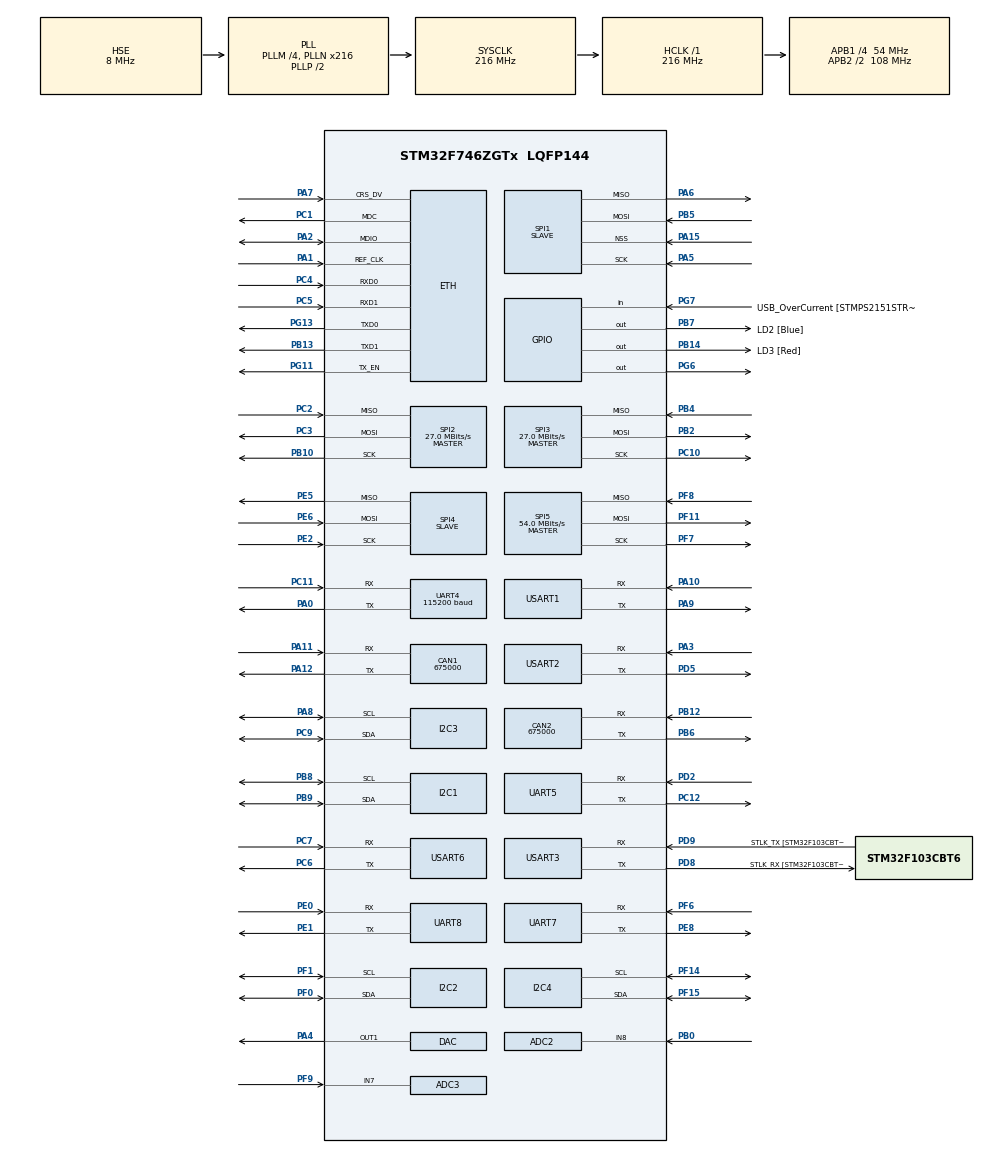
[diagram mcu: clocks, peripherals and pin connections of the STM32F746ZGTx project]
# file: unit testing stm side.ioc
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ADC1.Channel-1\#ChannelRegularConversion=ADC_CHANNEL_8
ADC1.ClockPrescaler=ADC_CLOCK_SYNC_PCLK_DIV4
ADC1.NbrOfConversionFlag=1
ADC1.Rank-1\#ChannelRegularConversion=1
ADC1.SamplingTime-1\#ChannelRegularConversion=ADC_SAMPLETIME_3CYCLES
ADC1.master=1
ADC2.Channel-2\#ChannelRegularConversion=ADC_CHANNEL_8
ADC2.ClockPrescaler=ADC_CLOCK_SYNC_PCLK_DIV4
ADC2.NbrOfConversionFlag=1
ADC2.Rank-2\#ChannelRegularConversion=1
ADC2.SamplingTime-2\#ChannelRegularConversion=ADC_SAMPLETIME_3CYCLES
ADC3.Channel-0\#ChannelRegularConversion=ADC_CHANNEL_7
ADC3.ClockPrescaler=ADC_CLOCK_SYNC_PCLK_DIV4
ADC3.NbrOfConversionFlag=1
ADC3.Rank-0\#ChannelRegularConversion=1
ADC3.SamplingTime-0\#ChannelRegularConversion=ADC_SAMPLETIME_3CYCLES
CAN1.BS1=CAN_BS1_2TQ
CAN1.BS2=CAN_BS2_2TQ
CAN1.CalculateBaudRate=675000
CAN1.CalculateTimeBit=1481
CAN1.CalculateTimeQuantum=296.2962962962963
CAN2.BS1=CAN_BS1_2TQ
CAN2.BS2=CAN_BS2_2TQ
CAN2.CalculateBaudRate=675000
CAN2.CalculateTimeBit=1481
CAN2.CalculateTimeQuantum=296.2962962962963
Dma.I2C1_RX.0.Direction=DMA_PERIPH_TO_MEMORY
Dma.I2C1_RX.0.FIFOMode=DMA_FIFOMODE_DISABLE
Dma.I2C1_RX.0.Instance=DMA1_Stream5
Dma.I2C1_RX.0.MemDataAlignment=DMA_MDATAALIGN_BYTE
Dma.I2C1_RX.0.MemInc=DMA_MINC_ENABLE
Dma.I2C1_RX.0.Mode=DMA_NORMAL
Dma.I2C1_RX.0.PeriphDataAlignment=DMA_PDATAALIGN_BYTE
Dma.I2C1_RX.0.PeriphInc=DMA_PINC_DISABLE
Dma.I2C1_RX.0.Priority=DMA_PRIORITY_LOW
Dma.I2C3_RX.8.Direction=DMA_PERIPH_TO_MEMORY
Dma.I2C3_RX.8.FIFOMode=DMA_FIFOMODE_DISABLE
Dma.I2C3_RX.8.Instance=DMA1_Stream1
Dma.I2C3_RX.8.MemDataAlignment=DMA_MDATAALIGN_BYTE
Dma.I2C3_RX.8.MemInc=DMA_MINC_ENABLE
Dma.I2C3_RX.8.Mode=DMA_NORMAL
Dma.I2C3_RX.8.PeriphDataAlignment=DMA_PDATAALIGN_BYTE
Dma.I2C3_RX.8.PeriphInc=DMA_PINC_DISABLE
Dma.I2C3_RX.8.Priority=DMA_PRIORITY_LOW
Dma.Request0=I2C1_RX
Dma.Request1=SPI1_RX
Dma.Request10=SPI4_TX
Dma.Request11=UART8_RX
Dma.Request12=USART1_RX
Dma.Request13=USART1_TX
Dma.Request14=USART6_RX
Dma.Request15=USART6_TX
Dma.Request2=SPI2_RX
Dma.Request3=UART4_TX
Dma.Request4=UART5_TX
Dma.Request5=SPI1_TX
Dma.Request6=UART4_RX
Dma.Request7=UART5_RX
Dma.Request8=I2C3_RX
Dma.Request9=SPI4_RX
Dma.SPI1_RX.1.Direction=DMA_PERIPH_TO_MEMORY
Dma.SPI1_RX.1.FIFOMode=DMA_FIFOMODE_DISABLE
Dma.SPI1_RX.1.Instance=DMA2_Stream2
Dma.SPI1_RX.1.MemDataAlignment=DMA_MDATAALIGN_BYTE
Dma.SPI1_RX.1.MemInc=DMA_MINC_ENABLE
Dma.SPI1_RX.1.Mode=DMA_NORMAL
Dma.SPI1_RX.1.PeriphDataAlignment=DMA_PDATAALIGN_BYTE
Dma.SPI1_RX.1.PeriphInc=DMA_PINC_DISABLE
Dma.SPI1_RX.1.Priority=DMA_PRIORITY_LOW
Dma.SPI1_TX.5.Direction=DMA_MEMORY_TO_PERIPH
Dma.SPI1_TX.5.FIFOMode=DMA_FIFOMODE_DISABLE
Dma.SPI1_TX.5.Instance=DMA2_Stream3
Dma.SPI1_TX.5.MemDataAlignment=DMA_MDATAALIGN_BYTE
Dma.SPI1_TX.5.MemInc=DMA_MINC_ENABLE
Dma.SPI1_TX.5.Mode=DMA_NORMAL
Dma.SPI1_TX.5.PeriphDataAlignment=DMA_PDATAALIGN_BYTE
Dma.SPI1_TX.5.PeriphInc=DMA_PINC_DISABLE
Dma.SPI1_TX.5.Priority=DMA_PRIORITY_LOW
Dma.SPI2_RX.2.Direction=DMA_PERIPH_TO_MEMORY
Dma.SPI2_RX.2.FIFOMode=DMA_FIFOMODE_DISABLE
Dma.SPI2_RX.2.Instance=DMA1_Stream3
Dma.SPI2_RX.2.MemDataAlignment=DMA_MDATAALIGN_BYTE
Dma.SPI2_RX.2.MemInc=DMA_MINC_ENABLE
Dma.SPI2_RX.2.Mode=DMA_NORMAL
Dma.SPI2_RX.2.PeriphDataAlignment=DMA_PDATAALIGN_BYTE
Dma.SPI2_RX.2.PeriphInc=DMA_PINC_DISABLE
Dma.SPI2_RX.2.Priority=DMA_PRIORITY_LOW
Dma.SPI4_RX.9.Direction=DMA_PERIPH_TO_MEMORY
Dma.SPI4_RX.9.FIFOMode=DMA_FIFOMODE_DISABLE
Dma.SPI4_RX.9.Instance=DMA2_Stream0
Dma.SPI4_RX.9.MemDataAlignment=DMA_MDATAALIGN_BYTE
Dma.SPI4_RX.9.MemInc=DMA_MINC_ENABLE
Dma.SPI4_RX.9.Mode=DMA_NORMAL
Dma.SPI4_RX.9.PeriphDataAlignment=DMA_PDATAALIGN_BYTE
Dma.SPI4_RX.9.PeriphInc=DMA_PINC_DISABLE
Dma.SPI4_RX.9.Priority=DMA_PRIORITY_LOW
Dma.SPI4_TX.10.Direction=DMA_MEMORY_TO_PERIPH
Dma.SPI4_TX.10.FIFOMode=DMA_FIFOMODE_DISABLE
Dma.SPI4_TX.10.Instance=DMA2_Stream4
Dma.SPI4_TX.10.MemDataAlignment=DMA_MDATAALIGN_BYTE
Dma.SPI4_TX.10.MemInc=DMA_MINC_ENABLE
Dma.SPI4_TX.10.Mode=DMA_NORMAL
Dma.SPI4_TX.10.PeriphDataAlignment=DMA_PDATAALIGN_BYTE
Dma.SPI4_TX.10.PeriphInc=DMA_PINC_DISABLE
Dma.SPI4_TX.10.Priority=DMA_PRIORITY_LOW
Dma.UART4_RX.6.Direction=DMA_PERIPH_TO_MEMORY
Dma.UART4_RX.6.FIFOMode=DMA_FIFOMODE_DISABLE
Dma.UART4_RX.6.Instance=DMA1_Stream2
Dma.UART4_RX.6.MemDataAlignment=DMA_MDATAALIGN_BYTE
Dma.UART4_RX.6.MemInc=DMA_MINC_ENABLE
Dma.UART4_RX.6.Mode=DMA_NORMAL
Dma.UART4_RX.6.PeriphDataAlignment=DMA_PDATAALIGN_BYTE
Dma.UART4_RX.6.PeriphInc=DMA_PINC_DISABLE
Dma.UART4_RX.6.Priority=DMA_PRIORITY_LOW
Dma.UART4_TX.3.Direction=DMA_MEMORY_TO_PERIPH
Dma.UART4_TX.3.FIFOMode=DMA_FIFOMODE_DISABLE
Dma.UART4_TX.3.Instance=DMA1_Stream4
Dma.UART4_TX.3.MemDataAlignment=DMA_MDATAALIGN_BYTE
Dma.UART4_TX.3.MemInc=DMA_MINC_ENABLE
Dma.UART4_TX.3.Mode=DMA_NORMAL
Dma.UART4_TX.3.PeriphDataAlignment=DMA_PDATAALIGN_BYTE
Dma.UART4_TX.3.PeriphInc=DMA_PINC_DISABLE
Dma.UART4_TX.3.Priority=DMA_PRIORITY_LOW
Dma.UART5_RX.7.Direction=DMA_PERIPH_TO_MEMORY
Dma.UART5_RX.7.FIFOMode=DMA_FIFOMODE_DISABLE
Dma.UART5_RX.7.Instance=DMA1_Stream0
Dma.UART5_RX.7.MemDataAlignment=DMA_MDATAALIGN_BYTE
Dma.UART5_RX.7.MemInc=DMA_MINC_ENABLE
Dma.UART5_RX.7.Mode=DMA_NORMAL
Dma.UART5_RX.7.PeriphDataAlignment=DMA_PDATAALIGN_BYTE
Dma.UART5_RX.7.PeriphInc=DMA_PINC_DISABLE
Dma.UART5_RX.7.Priority=DMA_PRIORITY_LOW
Dma.UART5_TX.4.Direction=DMA_MEMORY_TO_PERIPH
Dma.UART5_TX.4.FIFOMode=DMA_FIFOMODE_DISABLE
Dma.UART5_TX.4.Instance=DMA1_Stream7
Dma.UART5_TX.4.MemDataAlignment=DMA_MDATAALIGN_BYTE
Dma.UART5_TX.4.MemInc=DMA_MINC_ENABLE
Dma.UART5_TX.4.Mode=DMA_NORMAL
Dma.UART5_TX.4.PeriphDataAlignment=DMA_PDATAALIGN_BYTE
Dma.UART5_TX.4.PeriphInc=DMA_PINC_DISABLE
Dma.UART5_TX.4.Priority=DMA_PRIORITY_LOW
Dma.UART8_RX.11.Direction=DMA_PERIPH_TO_MEMORY
Dma.UART8_RX.11.FIFOMode=DMA_FIFOMODE_DISABLE
Dma.UART8_RX.11.Instance=DMA1_Stream6
Dma.UART8_RX.11.MemDataAlignment=DMA_MDATAALIGN_BYTE
Dma.UART8_RX.11.MemInc=DMA_MINC_ENABLE
Dma.UART8_RX.11.Mode=DMA_NORMAL
Dma.UART8_RX.11.PeriphDataAlignment=DMA_PDATAALIGN_BYTE
Dma.UART8_RX.11.PeriphInc=DMA_PINC_DISABLE
Dma.UART8_RX.11.Priority=DMA_PRIORITY_LOW
Dma.USART1_RX.12.Direction=DMA_PERIPH_TO_MEMORY
Dma.USART1_RX.12.FIFOMode=DMA_FIFOMODE_DISABLE
Dma.USART1_RX.12.Instance=DMA2_Stream5
Dma.USART1_RX.12.MemDataAlignment=DMA_MDATAALIGN_BYTE
Dma.USART1_RX.12.MemInc=DMA_MINC_ENABLE
Dma.USART1_RX.12.Mode=DMA_NORMAL
Dma.USART1_RX.12.PeriphDataAlignment=DMA_PDATAALIGN_BYTE
Dma.USART1_RX.12.PeriphInc=DMA_PINC_DISABLE
Dma.USART1_RX.12.Priority=DMA_PRIORITY_LOW
Dma.USART1_TX.13.Direction=DMA_MEMORY_TO_PERIPH
Dma.USART1_TX.13.FIFOMode=DMA_FIFOMODE_DISABLE
Dma.USART1_TX.13.Instance=DMA2_Stream7
Dma.USART1_TX.13.MemDataAlignment=DMA_MDATAALIGN_BYTE
Dma.USART1_TX.13.MemInc=DMA_MINC_ENABLE
Dma.USART1_TX.13.Mode=DMA_NORMAL
Dma.USART1_TX.13.PeriphDataAlignment=DMA_PDATAALIGN_BYTE
Dma.USART1_TX.13.PeriphInc=DMA_PINC_DISABLE
Dma.USART1_TX.13.Priority=DMA_PRIORITY_LOW
Dma.USART6_RX.14.Direction=DMA_PERIPH_TO_MEMORY
Dma.USART6_RX.14.FIFOMode=DMA_FIFOMODE_DISABLE
Dma.USART6_RX.14.Instance=DMA2_Stream1
Dma.USART6_RX.14.MemDataAlignment=DMA_MDATAALIGN_BYTE
Dma.USART6_RX.14.MemInc=DMA_MINC_ENABLE
Dma.USART6_RX.14.Mode=DMA_NORMAL
Dma.USART6_RX.14.PeriphDataAlignment=DMA_PDATAALIGN_BYTE
Dma.USART6_RX.14.PeriphInc=DMA_PINC_DISABLE
Dma.USART6_RX.14.Priority=DMA_PRIORITY_LOW
Dma.USART6_TX.15.Direction=DMA_MEMORY_TO_PERIPH
Dma.USART6_TX.15.FIFOMode=DMA_FIFOMODE_DISABLE
Dma.USART6_TX.15.Instance=DMA2_Stream6
Dma.USART6_TX.15.MemDataAlignment=DMA_MDATAALIGN_BYTE
Dma.USART6_TX.15.MemInc=DMA_MINC_ENABLE
Dma.USART6_TX.15.Mode=DMA_NORMAL
Dma.USART6_TX.15.PeriphDataAlignment=DMA_PDATAALIGN_BYTE
Dma.USART6_TX.15.PeriphInc=DMA_PINC_DISABLE
Dma.USART6_TX.15.Priority=DMA_PRIORITY_LOW
ETH.MediaInterface=HAL_ETH_RMII_MODE
FREERTOS.Tasks01=defaultTask,0,128,StartDefaultTask,Default,NULL,Dynamic,NULL,NULL
FREERTOS.configTOTAL_HEAP_SIZE=100000
FREERTOS.configUSE_NEWLIB_REENTRANT=1
I2C1.Timing=0x20404768
I2C2.Timing=0x20404768
I2C3.Timing=0x20404768
I2C4.Timing=0x20404768
LWIP.BSP.number=1
LWIP.GATEWAY_ADDRESS=192.168.008.001
LWIP.IP_ADDRESS=192.168.008.002
LWIP.LWIP_DHCP=0
LWIP.MEMP_NUM_RAW_PCB=10
LWIP.MEMP_NUM_UDP_PCB=10
LWIP.MEM_SIZE=10000
LWIP.NETMASK_ADDRESS=255.255.255.000
LWIP.Version=v2.1.2_Cube
LWIP0.BSP.STBoard=false
LWIP0.BSP.api=BSP_COMPONENT_DRIVER
LWIP0.BSP.component=LAN8742
LWIP0.BSP.instance=LAN8742
LWIP0.BSP.name=Driver_PHY
LWIP0.BSP.semaphore=S_LAN8742
LWIP0.BSP.solution=LAN8742
Mcu.Family=STM32F7
Mcu.Name=STM32F746ZGTx
Mcu.Package=LQFP144
NVIC.CAN1_RX0_IRQn=true\:5\:0\:false\:false\:true\:true\:true\:true\:true
NVIC.CAN1_RX1_IRQn=true\:5\:0\:false\:false\:true\:true\:true\:true\:true
NVIC.CAN1_SCE_IRQn=true\:5\:0\:false\:false\:true\:true\:true\:true\:true
NVIC.CAN1_TX_IRQn=true\:5\:0\:false\:false\:true\:true\:true\:true\:true
NVIC.DMA1_Stream0_IRQn=true\:5\:0\:false\:false\:true\:true\:false\:true\:true
NVIC.DMA1_Stream1_IRQn=true\:5\:0\:false\:false\:true\:true\:false\:true\:true
NVIC.DMA1_Stream2_IRQn=true\:5\:0\:false\:false\:true\:true\:false\:true\:true
NVIC.DMA1_Stream3_IRQn=true\:5\:0\:false\:false\:true\:true\:false\:true\:true
NVIC.DMA1_Stream4_IRQn=true\:5\:0\:false\:false\:true\:true\:false\:true\:true
NVIC.DMA1_Stream5_IRQn=true\:5\:0\:false\:false\:true\:false\:false\:true\:true
NVIC.DMA1_Stream6_IRQn=true\:5\:0\:false\:false\:true\:true\:false\:true\:true
NVIC.DMA1_Stream7_IRQn=true\:5\:0\:false\:false\:true\:true\:false\:true\:true
NVIC.DMA2_Stream0_IRQn=true\:5\:0\:false\:false\:true\:true\:false\:true\:true
NVIC.DMA2_Stream1_IRQn=true\:5\:0\:false\:false\:true\:true\:false\:true\:true
NVIC.DMA2_Stream2_IRQn=true\:5\:0\:false\:false\:true\:false\:false\:true\:true
NVIC.DMA2_Stream3_IRQn=true\:5\:0\:false\:false\:true\:true\:false\:true\:true
NVIC.DMA2_Stream4_IRQn=true\:5\:0\:false\:false\:true\:false\:false\:true\:true
NVIC.DMA2_Stream5_IRQn=true\:5\:0\:false\:false\:true\:true\:false\:true\:true
NVIC.DMA2_Stream6_IRQn=true\:5\:0\:false\:false\:true\:true\:false\:true\:true
NVIC.DMA2_Stream7_IRQn=true\:5\:0\:false\:false\:true\:true\:false\:true\:true
NVIC.ETH_IRQn=true\:5\:0\:false\:false\:true\:true\:false\:true\:true
NVIC.ETH_WKUP_IRQn=true\:5\:0\:false\:false\:true\:true\:true\:true\:true
NVIC.FLASH_IRQn=true\:5\:0\:false\:false\:true\:true\:true\:true\:true
NVIC.I2C1_ER_IRQn=true\:5\:0\:false\:false\:true\:true\:true\:true\:true
NVIC.I2C1_EV_IRQn=true\:5\:0\:false\:false\:true\:true\:true\:true\:true
NVIC.I2C2_ER_IRQn=true\:5\:0\:false\:false\:true\:true\:true\:true\:true
NVIC.I2C2_EV_IRQn=true\:5\:0\:false\:false\:true\:true\:true\:true\:true
NVIC.I2C3_ER_IRQn=true\:5\:0\:false\:false\:true\:true\:true\:true\:true
NVIC.I2C3_EV_IRQn=true\:5\:0\:false\:false\:true\:true\:true\:true\:true
NVIC.I2C4_ER_IRQn=true\:5\:0\:false\:false\:true\:true\:true\:true\:true
NVIC.I2C4_EV_IRQn=true\:5\:0\:false\:false\:true\:true\:true\:true\:true
NVIC.PriorityGroup=NVIC_PRIORITYGROUP_4
NVIC.SPI1_IRQn=true\:5\:0\:false\:false\:true\:true\:true\:true\:true
NVIC.SPI2_IRQn=true\:5\:0\:false\:false\:true\:true\:true\:true\:true
NVIC.SPI3_IRQn=true\:5\:0\:false\:false\:true\:true\:true\:true\:true
NVIC.SPI4_IRQn=true\:5\:0\:false\:false\:true\:true\:true\:true\:true
NVIC.TIM1_UP_TIM10_IRQn=true\:15\:0\:false\:false\:true\:false\:false\:true\:true
NVIC.TimeBase=TIM1_UP_TIM10_IRQn
NVIC.TimeBaseIP=TIM1
NVIC.UART4_IRQn=true\:5\:0\:false\:false\:true\:true\:true\:true\:true
NVIC.UART5_IRQn=true\:5\:0\:false\:false\:true\:true\:true\:true\:true
NVIC.UART7_IRQn=true\:5\:0\:false\:false\:true\:true\:true\:true\:true
NVIC.UART8_IRQn=true\:5\:0\:false\:false\:true\:true\:true\:true\:true
NVIC.USART1_IRQn=true\:5\:0\:false\:false\:true\:true\:true\:true\:true
NVIC.USART2_IRQn=true\:5\:0\:false\:false\:true\:true\:true\:true\:true
NVIC.USART3_IRQn=true\:5\:0\:false\:false\:true\:true\:true\:true\:true
NVIC.USART6_IRQn=true\:5\:0\:false\:false\:true\:true\:true\:true\:true
PA0/WKUP.GPIO_PuPd=GPIO_PULLUP
PA0/WKUP.Mode=Asynchronous
PA0/WKUP.Signal=UART4_TX
PA1.Mode=RMII
PA1.Signal=ETH_REF_CLK
PA10.Mode=Asynchronous
PA10.Signal=USART1_RX
PA11.Mode=CAN_Activate
PA11.Signal=CAN1_RX
PA12.Mode=CAN_Activate
PA12.Signal=CAN1_TX
PA13.Mode=Serial_Wire
PA13.Signal=SYS_JTMS-SWDIO
PA14.GPIO_Label=TCK
PA14.Mode=Serial_Wire
PA14.Signal=SYS_JTCK-SWCLK
PA15.Mode=NSS_Signal_Hard_Input
PA15.Signal=SPI1_NSS
PA2.GPIO_Mode=GPIO_MODE_AF_PP
PA2.GPIO_PuPd=GPIO_NOPULL
PA2.GPIO_Speed=GPIO_SPEED_FREQ_VERY_HIGH
PA2.Mode=RMII
PA2.Signal=ETH_MDIO
PA3.Mode=Asynchronous
PA3.Signal=USART2_RX
PA4.Signal=COMP_DAC1_group
PA5.GPIO_PuPd=GPIO_NOPULL
PA5.Mode=Full_Duplex_Slave
PA5.Signal=SPI1_SCK
PA6.GPIO_PuPd=GPIO_PULLUP
PA6.Mode=Full_Duplex_Slave
PA6.Signal=SPI1_MISO
PA7.Mode=RMII
PA7.Signal=ETH_CRS_DV
PA8.Mode=I2C
PA8.Signal=I2C3_SCL
PA9.Mode=Asynchronous
PA9.Signal=USART1_TX
PB0.Signal=ADCx_IN8
PB10.GPIO_PuPd=GPIO_NOPULL
PB10.Mode=Full_Duplex_Master
PB10.Signal=SPI2_SCK
PB12.Mode=CAN_Activate
PB12.Signal=CAN2_RX
PB13.GPIO_Mode=GPIO_MODE_AF_PP
PB13.GPIO_PuPd=GPIO_NOPULL
PB13.GPIO_Speed=GPIO_SPEED_FREQ_VERY_HIGH
PB13.Mode=RMII
PB13.Signal=ETH_TXD1
PB14.GPIO_Label=LD3 [Red]
PB14.Signal=GPIO_Output
PB2.Mode=Full_Duplex_Master
PB2.Signal=SPI3_MOSI
PB3.GPIO_Label=SW0
PB3.Signal=SYS_JTDO-SWO
PB4.Mode=Full_Duplex_Master
PB4.Signal=SPI3_MISO
PB5.GPIO_PuPd=GPIO_PULLUP
PB5.Mode=Full_Duplex_Slave
PB5.Signal=SPI1_MOSI
PB6.Mode=CAN_Activate
PB6.Signal=CAN2_TX
PB7.GPIO_Label=LD2 [Blue]
PB7.Signal=GPIO_Output
PB8.GPIO_Pu=GPIO_PULLUP
PB8.Mode=I2C
PB8.Signal=I2C1_SCL
PB9.GPIO_Pu=GPIO_PULLUP
PB9.Mode=I2C
PB9.Signal=I2C1_SDA
PC1.GPIO_Mode=GPIO_MODE_AF_PP
PC1.GPIO_PuPd=GPIO_NOPULL
PC1.GPIO_Speed=GPIO_SPEED_FREQ_VERY_HIGH
PC1.Mode=RMII
PC1.Signal=ETH_MDC
PC10.Mode=Full_Duplex_Master
PC10.Signal=SPI3_SCK
PC11.GPIO_PuPd=GPIO_PULLUP
PC11.Mode=Asynchronous
PC11.Signal=UART4_RX
PC12.GPIO_PuPd=GPIO_PULLUP
PC12.Mode=Asynchronous
PC12.Signal=UART5_TX
PC14/OSC32_IN.Mode=LSE-External-Oscillator
PC14/OSC32_IN.Signal=RCC_OSC32_IN
PC15/OSC32_OUT.Mode=LSE-External-Oscillator
PC15/OSC32_OUT.Signal=RCC_OSC32_OUT
PC2.GPIO_PuPd=GPIO_PULLUP
PC2.Mode=Full_Duplex_Master
PC2.Signal=SPI2_MISO
PC3.GPIO_PuPd=GPIO_PULLUP
PC3.Mode=Full_Duplex_Master
PC3.Signal=SPI2_MOSI
PC4.GPIO_Mode=GPIO_MODE_AF_PP
PC4.GPIO_PuPd=GPIO_NOPULL
PC4.GPIO_Speed=GPIO_SPEED_FREQ_VERY_HIGH
PC4.Mode=RMII
PC4.Signal=ETH_RXD0
PC5.GPIO_Mode=GPIO_MODE_AF_PP
PC5.GPIO_PuPd=GPIO_NOPULL
PC5.GPIO_Speed=GPIO_SPEED_FREQ_VERY_HIGH
PC5.Mode=RMII
PC5.Signal=ETH_RXD1
PC6.Mode=Asynchronous
PC6.Signal=USART6_TX
PC7.Mode=Asynchronous
PC7.Signal=USART6_RX
PC9.Mode=I2C
PC9.Signal=I2C3_SDA
PD2.GPIO_PuPd=GPIO_PULLUP
PD2.Mode=Asynchronous
PD2.Signal=UART5_RX
PD5.Mode=Asynchronous
PD5.Signal=USART2_TX
PD8.GPIO_Label=STLK_RX [STM32F103CBT6_PA3]
PD8.GPIO_PuPd=GPIO_PULLUP
PD8.Mode=Asynchronous
PD8.Signal=USART3_TX
PD9.GPIO_Label=STLK_TX [STM32F103CBT6_PA2]
PD9.GPIO_PuPd=GPIO_PULLUP
PD9.Mode=Asynchronous
PD9.Signal=USART3_RX
PE0.Mode=Asynchronous
PE0.Signal=UART8_RX
PE1.Mode=Asynchronous
PE1.Signal=UART8_TX
PE2.Mode=Full_Duplex_Slave
PE2.Signal=SPI4_SCK
PE5.Mode=Full_Duplex_Slave
PE5.Signal=SPI4_MISO
PE6.Mode=Full_Duplex_Slave
PE6.Signal=SPI4_MOSI
PE8.Mode=Asynchronous
PE8.Signal=UART7_TX
PF0.GPIO_Pu=GPIO_PULLUP
PF0.Mode=I2C
PF0.Signal=I2C2_SDA
PF1.GPIO_Pu=GPIO_PULLUP
PF1.Mode=I2C
PF1.Signal=I2C2_SCL
PF11.Mode=Full_Duplex_Master
PF11.Signal=SPI5_MOSI
PF14.Mode=I2C
PF14.Signal=I2C4_SCL
PF15.Mode=I2C
PF15.Signal=I2C4_SDA
PF6.Mode=Asynchronous
PF6.Signal=UART7_RX
PF7.Mode=Full_Duplex_Master
PF7.Signal=SPI5_SCK
PF8.Mode=Full_Duplex_Master
PF8.Signal=SPI5_MISO
PF9.Mode=IN7
PF9.Signal=ADC3_IN7
PG11.GPIO_Mode=GPIO_MODE_AF_PP
PG11.GPIO_PuPd=GPIO_NOPULL
PG11.GPIO_Speed=GPIO_SPEED_FREQ_VERY_HIGH
PG11.Mode=RMII
PG11.Signal=ETH_TX_EN
PG13.GPIO_Mode=GPIO_MODE_AF_PP
PG13.GPIO_PuPd=GPIO_NOPULL
PG13.GPIO_Speed=GPIO_SPEED_FREQ_VERY_HIGH
PG13.Mode=RMII
PG13.Signal=ETH_TXD0
PG6.Signal=GPIO_Output
PG7.GPIO_Label=USB_OverCurrent [STMPS2151STR_FAULT]
PG7.Signal=GPIO_Input
PH0/OSC_IN.GPIO_Label=MCO [STM32F103CBT6_PA8]
PH0/OSC_IN.Mode=HSE-External-Clock-Source
PH0/OSC_IN.Signal=RCC_OSC_IN
PH1/OSC_OUT.Mode=HSE-External-Clock-Source
PH1/OSC_OUT.Signal=RCC_OSC_OUT
ProjectManager.HeapSize=0x200
ProjectManager.StackSize=0x400
ProjectManager.TargetToolchain=STM32CubeIDE
RCC.48MHZClocksFreq_Value=24000000
RCC.AHBFreq_Value=216000000
RCC.APB1CLKDivider=RCC_HCLK_DIV4
RCC.APB1Freq_Value=54000000
RCC.APB1TimFreq_Value=108000000
RCC.APB2CLKDivider=RCC_HCLK_DIV2
RCC.APB2Freq_Value=108000000
RCC.APB2TimFreq_Value=216000000
RCC.CortexFreq_Value=216000000
RCC.HCLKFreq_Value=216000000
RCC.HSE_VALUE=8000000
RCC.HSI_VALUE=16000000
RCC.PLLM=4
RCC.PLLMUL=RCC_PLL_MUL9
RCC.PLLN=216
RCC.PLLQ=3
RCC.PLLSourceVirtual=RCC_PLLSOURCE_HSE
RCC.PRESCALERUSB=RCC_USBCLKSOURCE_PLL_DIV1_5
RCC.SYSCLKFreq_VALUE=216000000
RCC.SYSCLKSource=RCC_SYSCLKSOURCE_PLLCLK
RCC.SYSCLKSourceVirtual=RCC_SYSCLKSOURCE_PLLCLK
RCC.USBFreq_Value=144000000
RCC.VCOOutputFreq_Value=432000000
SH.ADCx_IN8.0=ADC2_IN8,IN8
SH.ADCx_IN8.1=ADC1_IN8,IN8
SH.COMP_DAC1_group.0=DAC_OUT1,DAC_OUT1
SPI1.DataSize=SPI_DATASIZE_8BIT
SPI1.Direction=SPI_DIRECTION_2LINES
SPI1.Mode=SPI_MODE_SLAVE
SPI1.VirtualNSS=VM_NSSHARD
SPI1.VirtualType=VM_SLAVE
SPI2.CalculateBaudRate=27.0 MBits/s
SPI2.DataSize=SPI_DATASIZE_8BIT
SPI2.Direction=SPI_DIRECTION_2LINES
SPI2.Mode=SPI_MODE_MASTER
SPI2.VirtualType=VM_MASTER
SPI3.CalculateBaudRate=27.0 MBits/s
SPI3.Direction=SPI_DIRECTION_2LINES
SPI3.Mode=SPI_MODE_MASTER
SPI3.VirtualType=VM_MASTER
SPI4.Direction=SPI_DIRECTION_2LINES
SPI4.Mode=SPI_MODE_SLAVE
SPI4.VirtualType=VM_SLAVE
SPI5.CalculateBaudRate=54.0 MBits/s
SPI5.Direction=SPI_DIRECTION_2LINES
SPI5.Mode=SPI_MODE_MASTER
SPI5.VirtualType=VM_MASTER
UART4.BaudRate=115200
USART1.VirtualMode-Asynchronous=VM_ASYNC
USART2.VirtualMode-Asynchronous=VM_ASYNC
USART3.VirtualMode-Asynchronous=VM_ASYNC
USART6.VirtualMode-Asynchronous=VM_ASYNC
VP_FREERTOS_VS_CMSIS_V1.Mode=CMSIS_V1
VP_LWIP_VS_Enabled.Mode=Enabled
VP_SYS_VS_tim1.Mode=TIM1
board=NUCLEO-F746ZG

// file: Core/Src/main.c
/* USER CODE BEGIN Header */
/**
  ******************************************************************************
  * @file           : main.c
  * @brief          : Main program body
  ******************************************************************************
  * @attention
  *
  * Copyright (c) 2024 STMicroelectronics.
  * All rights reserved.
  *
  * This software is licensed under terms that can be found in the LICENSE file
  * in the root directory of this software component.
  * If no LICENSE file comes with this software, it is provided AS-IS.
  *
  ******************************************************************************
  */
/* USER CODE END Header */
#include "main.h"
#include "cmsis_os.h"
#include "adc.h"
#include "can.h"
#include "dac.h"
#include "dma.h"
#include "i2c.h"
#include "lwip.h"
#include "spi.h"
#include "usart.h"
#include "gpio.h"

void SystemClock_Config(void);
void MX_FREERTOS_Init(void);

int main(void)
{

  /* MCU Configuration--------------------------------------------------------*/

  /* Reset of all peripherals, Initializes the Flash interface and the Systick. */
  HAL_Init();

  /* Configure the system clock */
  SystemClock_Config();

  /* Initialize all configured peripherals */
  MX_GPIO_Init();
  MX_DMA_Init();
  MX_I2C1_Init();
  MX_I2C2_Init();
  MX_SPI1_Init();
  MX_SPI2_Init();
  MX_UART4_Init();
  MX_UART5_Init();
  MX_ADC1_Init();
  MX_ADC2_Init();
  MX_ADC3_Init();
  MX_DAC_Init();
  MX_I2C3_Init();
  MX_I2C4_Init();
  MX_SPI3_Init();
  MX_SPI4_Init();
  MX_SPI5_Init();
  MX_UART7_Init();
  MX_UART8_Init();
  MX_USART1_UART_Init();
  MX_USART2_UART_Init();
  MX_USART3_UART_Init();
  MX_USART6_UART_Init();
  MX_CAN1_Init();
  MX_CAN2_Init();
  /* USER CODE BEGIN 2 */
  ur_main();
  /* USER CODE END 2 */

  /* Call init function for freertos objects (in freertos.c) */
  MX_FREERTOS_Init();

  /* Start scheduler */
  osKernelStart();

  /* We should never get here as control is now taken by the scheduler */
  /* Infinite loop */
  while (1)
  {

  }
}

void SystemClock_Config(void)
{
  RCC_OscInitTypeDef RCC_OscInitStruct = {0};
  RCC_ClkInitTypeDef RCC_ClkInitStruct = {0};

  /** Configure LSE Drive Capability
  */
  HAL_PWR_EnableBkUpAccess();

  /** Configure the main internal regulator output voltage
  */
  __HAL_RCC_PWR_CLK_ENABLE();
  __HAL_PWR_VOLTAGESCALING_CONFIG(PWR_REGULATOR_VOLTAGE_SCALE1);

  /** Initializes the RCC Oscillators according to the specified parameters
  * in the RCC_OscInitTypeDef structure.
  */
  RCC_OscInitStruct.OscillatorType = RCC_OSCILLATORTYPE_HSE;
  RCC_OscInitStruct.HSEState = RCC_HSE_BYPASS;
  RCC_OscInitStruct.PLL.PLLState = RCC_PLL_ON;
  RCC_OscInitStruct.PLL.PLLSource = RCC_PLLSOURCE_HSE;
  RCC_OscInitStruct.PLL.PLLM = 4;
  RCC_OscInitStruct.PLL.PLLN = 216;
  RCC_OscInitStruct.PLL.PLLP = RCC_PLLP_DIV2;
  RCC_OscInitStruct.PLL.PLLQ = 3;
  if (HAL_RCC_OscConfig(&RCC_OscInitStruct) != HAL_OK)
  {
    Error_Handler();
  }

  /** Activate the Over-Drive mode
  */
  if (HAL_PWREx_EnableOverDrive() != HAL_OK)
  {
    Error_Handler();
  }

  /** Initializes the CPU, AHB and APB buses clocks
  */
  RCC_ClkInitStruct.ClockType = RCC_CLOCKTYPE_HCLK|RCC_CLOCKTYPE_SYSCLK
                              |RCC_CLOCKTYPE_PCLK1|RCC_CLOCKTYPE_PCLK2;
  RCC_ClkInitStruct.SYSCLKSource = RCC_SYSCLKSOURCE_PLLCLK;
  RCC_ClkInitStruct.AHBCLKDivider = RCC_SYSCLK_DIV1;
  RCC_ClkInitStruct.APB1CLKDivider = RCC_HCLK_DIV4;
  RCC_ClkInitStruct.APB2CLKDivider = RCC_HCLK_DIV2;

  if (HAL_RCC_ClockConfig(&RCC_ClkInitStruct, FLASH_LATENCY_7) != HAL_OK)
  {
    Error_Handler();
  }
}

void HAL_TIM_PeriodElapsedCallback(TIM_HandleTypeDef *htim)
{
  if (htim->Instance == TIM1) {
    HAL_IncTick();
  }
}

void Error_Handler(void)
{
  __disable_irq();
  while (1)
  {
  }
}

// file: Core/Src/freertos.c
/* USER CODE BEGIN Header */
/**
  ******************************************************************************
  * File Name          : freertos.c
  * Description        : Code for freertos applications
  ******************************************************************************
  * @attention
  *
  * Copyright (c) 2024 STMicroelectronics.
  * All rights reserved.
  *
  * This software is licensed under terms that can be found in the LICENSE file
  * in the root directory of this software component.
  * If no LICENSE file comes with this software, it is provided AS-IS.
  *
  ******************************************************************************
  */
/* USER CODE END Header */

#include "FreeRTOS.h"
#include "task.h"
#include "main.h"
#include "cmsis_os.h"

osThreadId defaultTaskHandle;

void StartDefaultTask(void const * argument);

extern void MX_LWIP_Init(void);
void MX_FREERTOS_Init(void); /* (MISRA C 2004 rule 8.1) */

/* GetIdleTaskMemory prototype (linked to static allocation support) */
void vApplicationGetIdleTaskMemory( StaticTask_t **ppxIdleTaskTCBBuffer, StackType_t **ppxIdleTaskStackBuffer, uint32_t *pulIdleTaskStackSize );

/* USER CODE BEGIN GET_IDLE_TASK_MEMORY */
static StaticTask_t xIdleTaskTCBBuffer;
static StackType_t xIdleStack[configMINIMAL_STACK_SIZE];

void vApplicationGetIdleTaskMemory( StaticTask_t **ppxIdleTaskTCBBuffer, StackType_t **ppxIdleTaskStackBuffer, uint32_t *pulIdleTaskStackSize )
{
  *ppxIdleTaskTCBBuffer = &xIdleTaskTCBBuffer;
  *ppxIdleTaskStackBuffer = &xIdleStack[0];
  *pulIdleTaskStackSize = configMINIMAL_STACK_SIZE;
  /* place for user code */
}
/* USER CODE END GET_IDLE_TASK_MEMORY */

void MX_FREERTOS_Init(void) {

  /* Create the thread(s) */
  /* definition and creation of defaultTask */
  osThreadDef(defaultTask, StartDefaultTask, osPriorityNormal, 0, 128);
  defaultTaskHandle = osThreadCreate(osThread(defaultTask), NULL);

}

void StartDefaultTask(void const * argument)
{
  /* init code for LWIP */
  MX_LWIP_Init();
  for(;;)
  {
    osDelay(1);
  }
}
